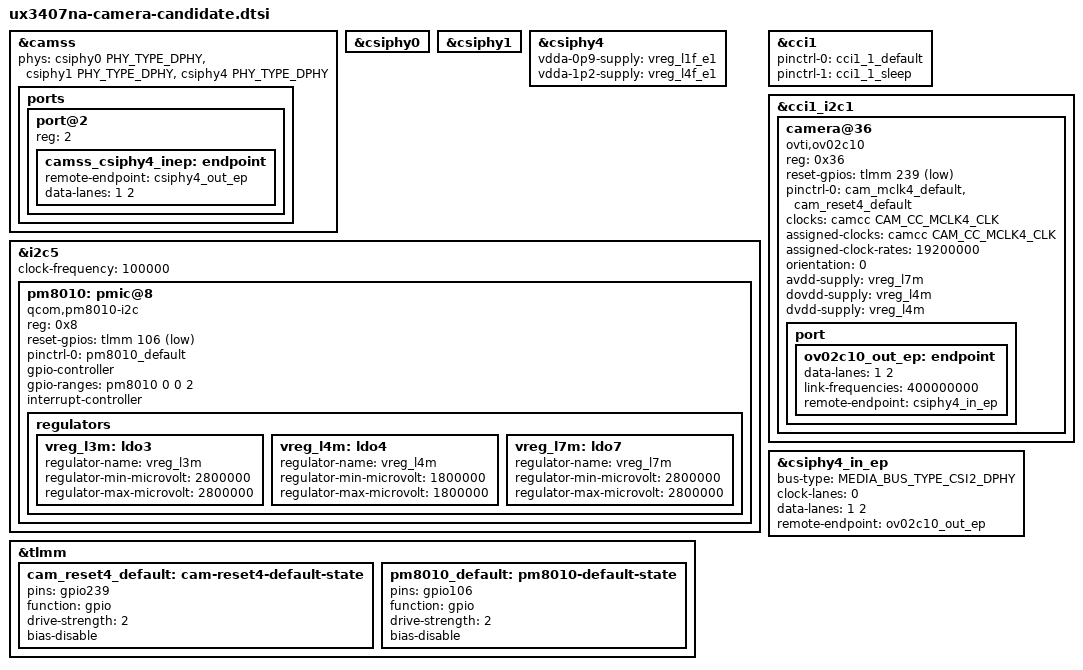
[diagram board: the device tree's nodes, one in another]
/*
 * UX3407NA front camera (OV02C10) -- CANDIDATE board graph, UNVERIFIED BY DEV OS.
 * Applied only by `prepare-board-fixes.py --enable-camera-candidate`, on a source tree that
 * already has native/kernel/ux3407na-camera/ (11 patches). Never part of a default build.
 *
 * Origin: community A14 description, chrispouliot/linux-zenbook-a14-arm `patches/a14-camera.dtsi`
 * (claims a probed OV02C10 and a working 1920x1092@30 libcamera stream on the UX3407NA),
 * itself modelled on the Glymur CRD / Zenbook A16 camera DT. Provenance per value:
 *   [ACPI] confirmed by this laptop's own DSDT      [SOC] defined by our SoC patch stack
 *   [COMM] third-party claim, not verifiable here   [A16] copied from the A16/CRD by that author
 *
 * Open (nothing in our evidence confirms): sensor reset GPIO 239 [COMM], PM8010 reset GPIO 106
 * [A16], LDO->rail mapping and voltages [A16], PM8010 input supplies (vdd-l3-l4, vdd-l7: not set
 * by the source), CSI lanes <1 2> / 400 MHz link [COMM], MCLK4 [COMM]. Details and sources:
 * native/kernel/ux3407na-camera/BOARD-EVIDENCE.md. The privacy LED link is omitted: the pinned
 * A14 DTS has no privacy_led node.
 */

#include <dt-bindings/media/video-interfaces.h>
#include <dt-bindings/phy/phy.h>

/* The pinned CAMSS driver consumes named PHYs, not only graph endpoints.
 * Glymur has hardware PHY IDs 0,1,4, stored at dense array indexes 0,1,2
 * by 0002-camss-glymur-phy-resources.patch. The CAMSS port uses that index.
 */
&camss {
	phys = <&csiphy0 PHY_TYPE_DPHY>, <&csiphy1 PHY_TYPE_DPHY>, <&csiphy4 PHY_TYPE_DPHY>;
	phy-names = "csiphy0", "csiphy1", "csiphy4";
	ports {
		/delete-node/ port@3;
		port@2 {
			reg = <2>;
			camss_csiphy4_inep: endpoint {
				remote-endpoint = <&csiphy4_out_ep>;
			};
		};
	};
};
&csiphy0 { #phy-cells = <1>; };
&csiphy1 { #phy-cells = <1>; };
&csiphy4 { #phy-cells = <1>; };

/* Camera PMIC, ACPI PML0: address 0x08, 100 kHz, controller 0xb94000 (= i2c5) [ACPI]. */
&i2c5 {
	clock-frequency = <100000>;
	status = "okay";

	pm8010: pmic@8 {
		compatible = "qcom,pm8010-i2c";		/* name used by our driver patches [SOC] */
		reg = <0x8>;				/* [ACPI] */

		reset-gpios = <&tlmm 106 GPIO_ACTIVE_LOW>;	/* [A16] */
		pinctrl-0 = <&pm8010_default>;
		pinctrl-names = "default";

		gpio-controller;
		#gpio-cells = <2>;
		gpio-ranges = <&pm8010 0 0 2>;

		interrupt-controller;
		#interrupt-cells = <2>;

		#thermal-sensor-cells = <0>;

		regulators {
			/* [A16] mapping and voltages */
			vreg_l3m: ldo3 {
				regulator-name = "vreg_l3m";
				regulator-min-microvolt = <2800000>;
				regulator-max-microvolt = <2800000>;
			};

			vreg_l4m: ldo4 {
				regulator-name = "vreg_l4m";
				regulator-min-microvolt = <1800000>;
				regulator-max-microvolt = <1800000>;
			};

			vreg_l7m: ldo7 {
				regulator-name = "vreg_l7m";
				regulator-min-microvolt = <2800000>;
				regulator-max-microvolt = <2800000>;
			};
		};
	};
};

&camss {
	status = "okay";
};

&camss_csiphy4_inep {
	data-lanes = <1 2>;				/* [COMM] */
};

&cci1 {
	pinctrl-0 = <&cci1_1_default>;			/* [SOC] gpio235/236 */
	pinctrl-1 = <&cci1_1_sleep>;
	status = "okay";
};

&cci1_i2c1 {
	/* Front RGB sensor: address 0x36 [ACPI-adjacent: Windows sensor config], bus cci1/1 [COMM]. */
	camera@36 {
		compatible = "ovti,ov02c10";
		reg = <0x36>;

		reset-gpios = <&tlmm 239 GPIO_ACTIVE_LOW>;	/* [COMM] */
		pinctrl-0 = <&cam_mclk4_default>, <&cam_reset4_default>;
		pinctrl-names = "default";

		clocks = <&camcc CAM_CC_MCLK4_CLK>;		/* [COMM]; [SOC] pin gpio100 */
		assigned-clocks = <&camcc CAM_CC_MCLK4_CLK>;
		assigned-clock-rates = <19200000>;		/* 19.2 MHz also found in the Windows module */

		orientation = <0>;

		avdd-supply = <&vreg_l7m>;			/* [A16] */
		dovdd-supply = <&vreg_l4m>;			/* [A16] */
		dvdd-supply = <&vreg_l4m>;			/* [A16] */

		port {
			ov02c10_out_ep: endpoint {
				data-lanes = <1 2>;		/* [COMM] */
				link-frequencies = /bits/ 64 <400000000>;	/* [COMM] */
				remote-endpoint = <&csiphy4_in_ep>;
			};
		};
	};
};

&csiphy4 {
	vdda-0p9-supply = <&vreg_l1f_e1>;		/* [A16]; rail exists in pinned A14 DTS */
	vdda-1p2-supply = <&vreg_l4f_e1>;		/* [A16] */
	status = "okay";
};

&csiphy4_in_ep {
	bus-type = <MEDIA_BUS_TYPE_CSI2_DPHY>;
	clock-lanes = <0>;
	data-lanes = <1 2>;				/* [COMM] */
	remote-endpoint = <&ov02c10_out_ep>;
};

&tlmm {
	cam_reset4_default: cam-reset4-default-state {
		pins = "gpio239";
		function = "gpio";
		drive-strength = <2>;
		bias-disable;
	};

	pm8010_default: pm8010-default-state {
		pins = "gpio106";
		function = "gpio";
		drive-strength = <2>;
		bias-disable;
	};
};
